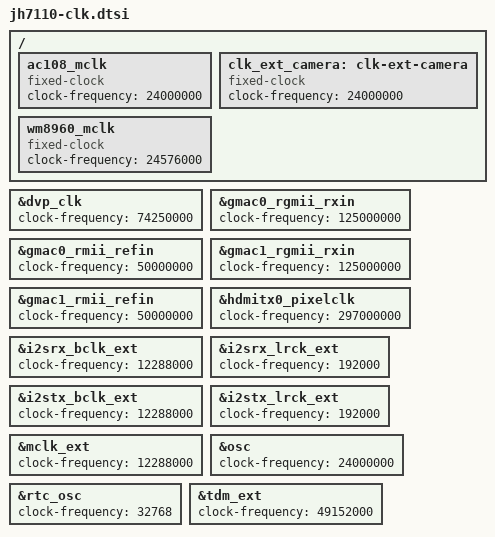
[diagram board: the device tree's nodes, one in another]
// SPDX-License-Identifier: GPL-2.0 OR MIT
/*
 * Copyright (C) 2023 StarFive Technology Co., Ltd.
 */

/ {
	ac108_mclk: ac108_mclk {
		compatible = "fixed-clock";
		#clock-cells = <0>;
		clock-frequency = <24000000>;
	};

	clk_ext_camera: clk-ext-camera {
		compatible = "fixed-clock";
		#clock-cells = <0>;
		clock-frequency = <24000000>;
	};

	wm8960_mclk: wm8960_mclk {
		compatible = "fixed-clock";
		#clock-cells = <0>;
		clock-frequency = <24576000>;
	};
};

&dvp_clk {
	clock-frequency = <74250000>;
};

&gmac0_rgmii_rxin {
	clock-frequency = <125000000>;
};

&gmac0_rmii_refin {
	clock-frequency = <50000000>;
};

&gmac1_rgmii_rxin {
	clock-frequency = <125000000>;
};

&gmac1_rmii_refin {
	clock-frequency = <50000000>;
};

&hdmitx0_pixelclk {
	clock-frequency = <297000000>;
};

&i2srx_bclk_ext {
	clock-frequency = <12288000>;
};

&i2srx_lrck_ext {
	clock-frequency = <192000>;
};

&i2stx_bclk_ext {
	clock-frequency = <12288000>;
};

&i2stx_lrck_ext {
	clock-frequency = <192000>;
};

&mclk_ext {
	clock-frequency = <12288000>;
};

&osc {
	clock-frequency = <24000000>;
};

&rtc_osc {
	clock-frequency = <32768>;
};

&tdm_ext {
	clock-frequency = <49152000>;
};
